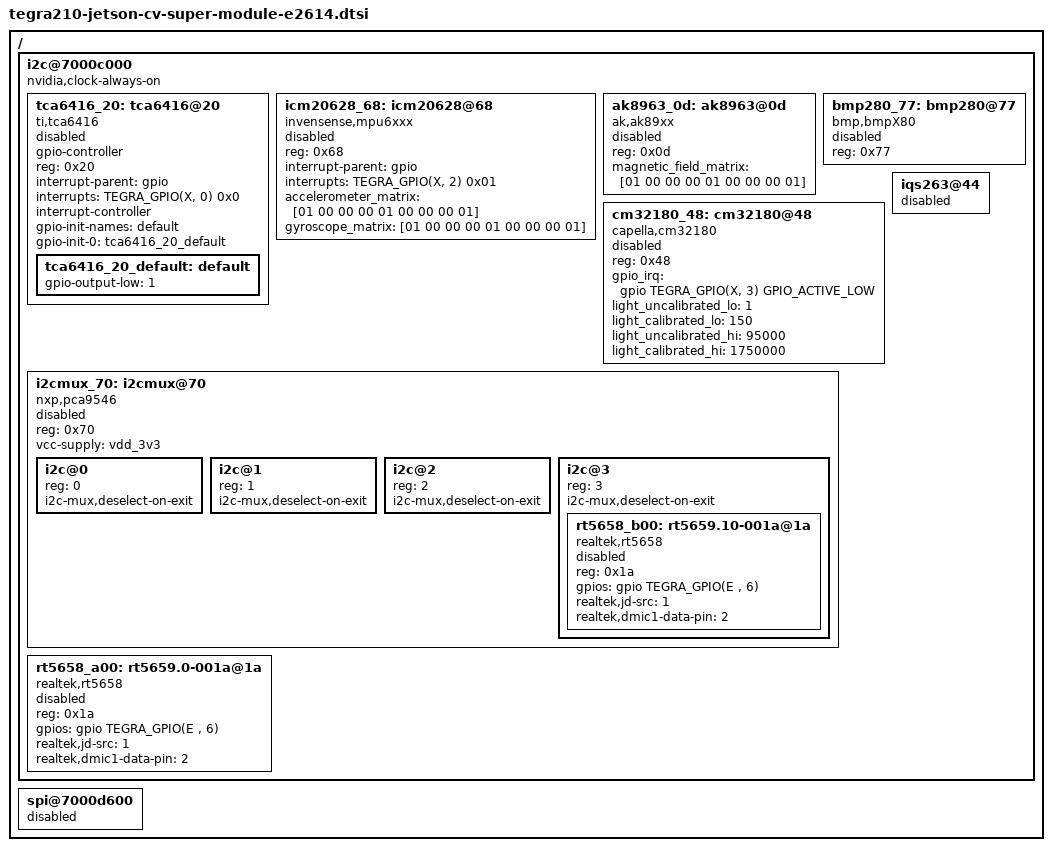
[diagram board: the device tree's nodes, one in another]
/*
 * Jetson-CV Super Module peripherals
 *
 * Copyright (c) 2015-2016, NVIDIA CORPORATION.  All rights reserved.
 *
 * This program is free software; you can redistribute it and/or modify
 * it under the terms of the GNU General Public License as published by
 * the Free Software Foundation; version 2 of the License.
 *
 * This program is distributed in the hope that it will be useful, but WITHOUT
 * ANY WARRANTY; without even the implied warranty of MERCHANTABILITY or
 * FITNESS FOR A PARTICULAR PURPOSE.  See the GNU General Public License for
 * more details.
 *
 */

/ {
	i2c@7000c000 {
		nvidia,clock-always-on;

		tca6416_20: tca6416@20 {
			compatible = "ti,tca6416";
			gpio-controller;
			#gpio-cells = <2>;
			reg = <0x20>;
			interrupt-parent = <&gpio>;
			interrupts = <TEGRA_GPIO(X, 0) 0x0>;
			#interrupt-cells = <2>;
			interrupt-controller;
			gpio-init-names = "default";
			gpio-init-0 = <&tca6416_20_default>;
			status = "disabled";
			tca6416_20_default: default {
				gpio-output-low = <1>;
			};
		};

		icm20628_68: icm20628@68 {
			compatible = "invensense,mpu6xxx";
			reg = <0x68>;
			interrupt-parent = <&gpio>;
			interrupts = <TEGRA_GPIO(X, 2) 0x01>;
                        accelerometer_matrix	= [01 00 00 00 01 00 00 00 01];
                        gyroscope_matrix	= [01 00 00 00 01 00 00 00 01];
			status = "disabled";
		};

		ak8963_0d: ak8963@0d {
			compatible = "ak,ak89xx";
			reg = <0x0d>;
                        magnetic_field_matrix = [01 00 00 00 01 00 00 00 01];
			status = "disabled";
		};

		bmp280_77: bmp280@77 {
			compatible = "bmp,bmpX80";
			reg = <0x77>;
			status = "disabled";
		};

		cm32180_48: cm32180@48 {
			compatible = "capella,cm32180";
			reg = <0x48>;
			gpio_irq = <&gpio TEGRA_GPIO(X, 3) GPIO_ACTIVE_LOW>;
			light_uncalibrated_lo = <1>;
			light_calibrated_lo = <150>;
			light_uncalibrated_hi = <95000>;
			light_calibrated_hi = <1750000>;
			status = "disabled";
		};

		iqs263@44 {
			status = "disabled";
		};

		i2cmux_70: i2cmux@70 {
			compatible = "nxp,pca9546";
			reg = <0x70>;
			#address-cells = <1>;
			#size-cells = <0>;
			vcc-supply = <&vdd_3v3>;
			status = "disabled";
			i2c@0 {
				reg = <0>;
				i2c-mux,deselect-on-exit;
				#address-cells = <1>;
				#size-cells = <0>;
			};
			i2c@1 {
				reg = <1>;
				i2c-mux,deselect-on-exit;
				#address-cells = <1>;
				#size-cells = <0>;
			};
			i2c@2 {
				reg = <2>;
				i2c-mux,deselect-on-exit;
				#address-cells = <1>;
				#size-cells = <0>;
			};
			i2c@3 {
				reg = <3>;
				i2c-mux,deselect-on-exit;
				#address-cells = <1>;
				#size-cells = <0>;
				rt5658_b00: rt5659.10-001a@1a {
					compatible = "realtek,rt5658";
					reg = <0x1a>;
					status = "disabled";
					/* gpio for jack detection */
					gpios = <&gpio TEGRA_GPIO(E , 6) GPIO_ACTIVE_HIGH>;

					/* refer include/sound/rt5659.h for the values to be used */
					realtek,jd-src = <1>; /* RT5659_JD3 */
					realtek,dmic1-data-pin = <2>; /* RT5659_DMIC1_DATA_GPIO5 */
				};
			};
		};

		rt5658_a00: rt5659.0-001a@1a {
			compatible = "realtek,rt5658";
			reg = <0x1a>;
			status = "disabled";
			gpios = <&gpio TEGRA_GPIO(E , 6) GPIO_ACTIVE_HIGH>;

			realtek,jd-src = <1>; /* RT5659_JD3 */
			realtek,dmic1-data-pin = <2>; /* RT5659_DMIC1_DATA_GPIO5 */
		};
	};

	spi@7000d600 {
		status = "disabled";
	};
};
